# S32K144W_M4 register map
Vendor: NXP Semiconductors; File version: 1.3
CPU: CM4 r0p1, little endian, MPU, FPU, VTOR, 4 interrupt priority bits
Registers are 32-bit, read-write, reset 0x0 unless marked. A register's access mark holds for its fields unless they carry their own. Offsets are from the block's base; [hi:lo] are bit positions; {n}, {i} and the like mark numbered series; 'fields as' and 'values as' point back to an identical list.

## EIM
Base 0x40019000
0x00 EIMCR — Error Injection Module Configuration Register
  [0] GEIEN — Global Error Injection Enable
    0=Disabled; 1=Enabled
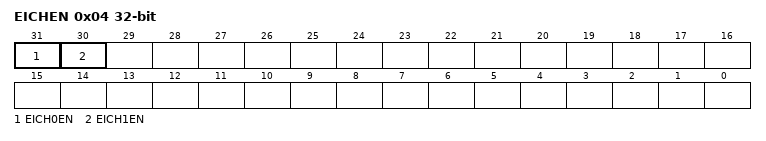
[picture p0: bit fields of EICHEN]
0x04 EICHEN — Error Injection Channel Enable register
  [31] EICH0EN — Error Injection Channel 0 Enable
    0=Error injection is disabled on Error Injection Channel 0; 1=Error injection is enabled on Error Injection Channel 0
  [30] EICH1EN — Error Injection Channel 1 Enable
    0=Error injection is disabled on Error Injection Channel 1; 1=Error injection is enabled on Error Injection Channel 1
0x100 EICHD0_WORD0 — Error Injection Channel Descriptor n, Word0
  [31:25] CHKBIT_MASK — Checkbit Mask
0x104 EICHD0_WORD1 — Error Injection Channel Descriptor n, Word1
  [31:0] B0_3DATA_MASK — Data Mask Bytes 0-3
0x140 EICHD1_WORD0 — Error Injection Channel Descriptor n, Word0
  [31:25] CHKBIT_MASK — Checkbit Mask
0x144 EICHD1_WORD1 — Error Injection Channel Descriptor n, Word1
  [31:0] B0_3DATA_MASK — Data Mask Bytes 0-3

## DMAMUX
Base 0x40021000
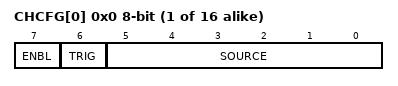
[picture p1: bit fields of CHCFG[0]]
{0x0+i} CHCFG[{i}] (i=0..15) 8-bit — Channel Configuration register
  [7] ENBL — DMA Channel Enable
    0=DMA channel is disabled. This mode is primarily used during configuration of the DMAMux. The DMA has separate channel enables/disables, which should be used to disable or reconfigure a DMA channel.; 1=DMA channel is enabled
  [6] TRIG — DMA Channel Trigger Enable
    0=Triggering is disabled. If triggering is disabled and ENBL is set, the DMA Channel will simply route the specified source to the DMA channel. (Normal mode); 1=Triggering is enabled. If triggering is enabled and ENBL is set, the DMAMUX is in Periodic Trigger mode.
  [5:0] SOURCE — DMA Channel Source (Slot)

## CRC
Base 0x40032000
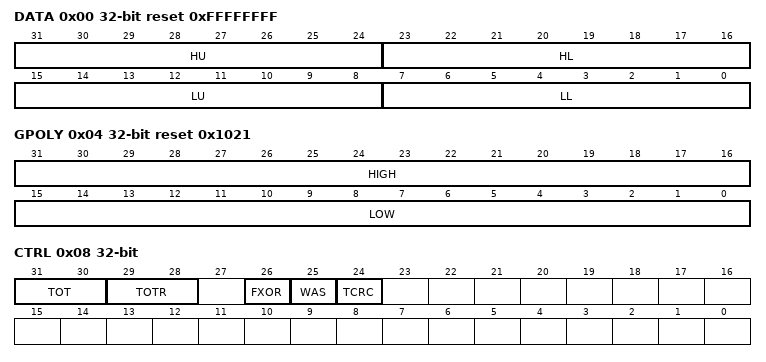
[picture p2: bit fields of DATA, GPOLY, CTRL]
0x00 DATA reset 0xFFFFFFFF — CRC Data register
  [31:24] HU — CRC High Upper Byte
  [23:16] HL — CRC High Lower Byte
  [15:8] LU — CRC Low Upper Byte
  [7:0] LL — CRC Low Lower Byte
0x04 GPOLY reset 0x1021 — CRC Polynomial register
  [31:16] HIGH — High Polynominal Half-word
  [15:0] LOW — Low Polynominal Half-word
0x08 CTRL — CRC Control register
  [31:30] TOT — Type Of Transpose For Writes
    0=No transposition; 1=Bits in bytes are transposed; bytes are not transposed; 2=Both bits in bytes and bytes are transposed; 3=Only bytes are transposed; no bits in a byte are transposed
  [29:28] TOTR — Type Of Transpose For Read
    values as TOT
  [26] FXOR — Complement Read Of CRC Data Register
    0=No XOR on reading; 1=Invert or complement the read value of the CRC Data register
  [25] WAS — Write CRC Data Register As Seed
    0=Writes to the CRC data register are data values; 1=Writes to the CRC data register are seed values
  [24] TCRC
    0=16-bit CRC protocol; 1=32-bit CRC protocol

## LPTMR0 — LPTMR
Base 0x40040000
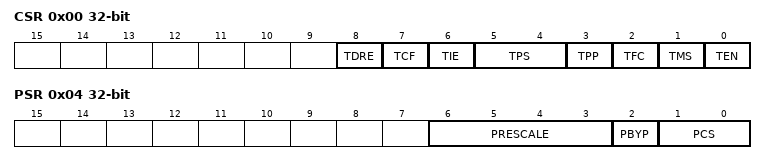
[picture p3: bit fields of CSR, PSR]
0x00 CSR — Low Power Timer Control Status Register
  [8] TDRE — Timer DMA Request Enable
    0=Timer DMA Request disabled; 1=Timer DMA Request enabled
  [7] TCF write-1-clears — Timer Compare Flag
    0=The value of CNR is not equal to CMR and increments; 1=The value of CNR is equal to CMR and increments
  [6] TIE — Timer Interrupt Enable
    0=Timer interrupt disabled; 1=Timer interrupt enabled
  [5:4] TPS — Timer Pin Select
    {v}=Pulse counter input {v} is selected (v=0..3)
  [3] TPP — Timer Pin Polarity
    0=Pulse Counter input source is active-high, and the CNR increments on the rising-edge; 1=Pulse Counter input source is active-low, and the CNR increments on the falling-edge
  [2] TFC — Timer Free-Running Counter
    0=CNR is reset whenever TCF is set; 1=CNR is reset on overflow
  [1] TMS — Timer Mode Select
    0=Time Counter mode; 1=Pulse Counter mode
  [0] TEN — Timer Enable
    0=LPTMR is disabled and internal logic is reset; 1=LPTMR is enabled
0x04 PSR — Low Power Timer Prescale Register
  [6:3] PRESCALE — Prescale Value
    0=Prescaler divides the prescaler clock by 2; glitch filter does not support this configuration; 1=Prescaler divides the prescaler clock by 4; glitch filter recognizes change on input pin after 2 rising clock edges; 2=Prescaler divides the prescaler clock by 8; glitch filter recognizes change on input pin after 4 rising clock edges; 3=Prescaler divides the prescaler clock by 16; glitch filter recognizes change on input pin after 8 rising clock edges; 4=Prescaler divides the prescaler clock by 32; glitch filter recognizes change on input pin after 16 rising clock edges; 5=Prescaler divides the prescaler clock by 64; glitch filter recognizes change on input pin after 32 rising clock edges; 6=Prescaler divides the prescaler clock by 128; glitch filter recognizes change on input pin after 64 rising clock edges; 7=Prescaler divides the prescaler clock by 256; glitch filter recognizes change on input pin after 128 rising clock edges; 8=Prescaler divides the prescaler clock by 512; glitch filter recognizes change on input pin after 256 rising clock edges; 9=Prescaler divides the prescaler clock by 1024; glitch filter recognizes change on input pin after 512 rising clock edges; 10=Prescaler divides the prescaler clock by 2048; glitch filter recognizes change on input pin after 1024 rising clock edges; 11=Prescaler divides the prescaler clock by 4096; glitch filter recognizes change on input pin after 2048 rising clock edges; 12=Prescaler divides the prescaler clock by 8192; glitch filter recognizes change on input pin after 4096 rising clock edges; 13=Prescaler divides the prescaler clock by 16,384; glitch filter recognizes change on input pin after 8192 rising clock edges; 14=Prescaler divides the prescaler clock by 32,768; glitch filter recognizes change on input pin after 16,384 rising clock edges; 15=Prescaler divides the prescaler clock by 65,536; glitch filter recognizes change on input pin after 32,768 rising clock edges
  [2] PBYP — Prescaler Bypass
    0=Prescaler/glitch filter is enabled; 1=Prescaler/glitch filter is bypassed
  [1:0] PCS — Prescaler Clock Select
    {v}=Prescaler/glitch filter clock {v} selected (v=0..3)
0x08 CMR — Low Power Timer Compare Register
  [15:0] COMPARE — Compare Value
0x0C CNR — Low Power Timer Counter Register
  [15:0] COUNTER — Counter Value

## Notices in the file
Copyright 2016-2021 NXP
NXP Confidential. This software is owned or controlled by NXP and may only be
used strictly in accordance with the applicable license terms. By expressly
accepting such terms or by downloading, installing, activating and/or otherwise
using the software, you are agreeing that you have read, and that you agree to
comply with and are bound by, such license terms. If you do not agree to be
bound by the applicable license terms, then you may not retain, install,
activate or otherwise use the software. The production use license in
Section 2.3 is expressly granted for this software.
